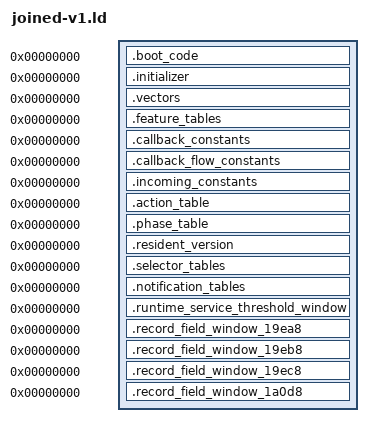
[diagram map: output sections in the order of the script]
OUTPUT_ARCH(riscv)
SECTIONS
{
 .boot_code 0 : SUBALIGN(2) { *(.boot_code)
  *(.text.tsl9_record_dispatch_provider_9658)
  *(.text.tsl9_record_field_transitions_block_9660)
  *(.text.tsl9_record_field_transitions_block_966a)
  *(.text.tsl9_record_field_transitions_block_969c)
  *(.text.tsl9_record_dispatch_provider_973c)
  *(.text.tsl9_record_field_transitions_block_9744)
  *(.text.tsl9_record_field_transitions_block_974e)
  *(.text.tsl9_record_field_transitions_block_978c)
  *(.text.tsl9_record_field_transitions_entry_a4cc)
  *(.text.tsl9_record_field_transitions_entry_a4d8)
  *(.text.tsl9_feature_external_a6d8)
  *(.text.tsl9_record_field_transitions_block_a710)
  *(.text.tsl9_record_field_transitions_block_a71c)
  *(.text.tsl9_record_field_transitions_block_a728)
  *(.text.tsl9_record_field_transitions_block_a734)
  *(.text.tsl9_record_field_transitions_block_a740)
  *(.text.tsl9_record_field_transitions_block_a76c)
  *(.text.tsl9_record_field_transitions_block_a780)
  *(.text.tsl9_record_field_transitions_block_a78c)
  *(.text.tsl9_record_field_transitions_block_a78e)
  *(.text.tsl9_record_field_transitions_block_a7a2)
  *(.text.tsl9_record_field_transitions_block_a7a6)
  *(.text.tsl9_record_field_transitions_block_a7b8)
  *(.text.tsl9_record_field_transitions_block_a7c0)
  *(.text.tsl9_record_field_transitions_block_a7ca)
  *(.text.tsl9_record_field_transitions_block_a7cc)
  *(.text.tsl9_record_field_transitions_block_a7d2)
  *(.text.tsl9_record_field_transitions_block_a7f0)
  *(.text.tsl9_record_field_transitions_block_a7f2)
  *(.text.tsl9_record_field_transitions_block_a7f8)
  *(.text.tsl9_record_field_transitions_block_a80a)
  *(.text.tsl9_record_field_transitions_block_a80e)
  *(.text.tsl9_record_field_transitions_block_a812)
  *(.text.tsl9_record_field_transitions_block_a81c)
  *(.text.tsl9_record_field_transitions_block_a81e)
  *(.text.tsl9_record_field_transitions_block_a824)
  *(.text.tsl9_record_field_transitions_block_a82e)
  *(.text.tsl9_record_field_transitions_block_a836)
  *(.text.tsl9_record_field_transitions_block_a840)
  *(.text.tsl9_record_field_transitions_block_a84a)
  *(.text.tsl9_record_field_transitions_block_a84c)
  *(.text.tsl9_record_field_transitions_block_a850)
  *(.text.tsl9_record_field_transitions_block_a85c)
  *(.text.tsl9_record_field_transitions_block_a85e)
  *(.text.tsl9_record_field_transitions_block_a860)
  *(.text.tsl9_record_field_transitions_block_a866)
  *(.text.tsl9_record_field_transitions_block_a870)
  *(.text.tsl9_record_field_transitions_block_a882)
  *(.text.tsl9_record_field_transitions_block_a888)
  *(.text.tsl9_record_field_transitions_block_a88c)
  *(.text.tsl9_record_field_transitions_block_a890)
  *(.text.tsl9_record_field_transitions_block_a89c)
  *(.text.tsl9_record_field_transitions_block_a8a0)
  *(.text.tsl9_record_field_transitions_block_a8a4)
  *(.text.tsl9_record_field_transitions_block_a8a6)
  *(.text.tsl9_record_field_transitions_block_a8aa)
  *(.text.tsl9_record_field_transitions_block_a8b6)
  *(.text.tsl9_record_field_transitions_block_a8c2)
  *(.text.tsl9_record_field_transitions_block_a8c6)
  *(.text.tsl9_record_field_transitions_block_a8ca)
  *(.text.tsl9_record_field_transitions_block_a8ce)
  *(.text.tsl9_record_field_transitions_block_a8d2)
  *(.text.tsl9_record_field_transitions_block_a8d4)
  *(.text.tsl9_record_field_transitions_block_a8da)
  *(.text.tsl9_record_field_transitions_block_a8e6)
  *(.text.tsl9_record_field_transitions_block_a8ec)
  *(.text.tsl9_record_field_transitions_block_a8f8)
  *(.text.tsl9_record_field_transitions_block_a8fe)
  *(.text.tsl9_record_field_transitions_block_a90c)
  *(.text.tsl9_record_field_transitions_block_a91a)
  *(.text.tsl9_record_field_transitions_block_a91e)
  *(.text.tsl9_record_field_transitions_block_a922)
  *(.text.tsl9_record_field_transitions_block_a93a)
  *(.text.tsl9_record_field_transitions_block_a940)
  *(.text.tsl9_record_field_transitions_block_a944)
  *(.text.tsl9_record_field_transitions_block_a954)
  *(.text.tsl9_record_field_transitions_block_a956)
  *(.text.tsl9_record_field_transitions_block_a95a)
  *(.text.tsl9_record_field_transitions_block_a95e)
  *(.text.tsl9_feature_external_b390)
  *(.text.tsl9_record_field_transitions_block_b3b8)
  *(.text.tsl9_record_field_transitions_block_b3c4)
  *(.text.tsl9_record_field_transitions_block_b3d8)
  *(.text.tsl9_feature_external_b402)
  *(.text.tsl9_record_field_transitions_block_b40c)
  *(.text.tsl9_record_field_transitions_block_b432)
  *(.text.tsl9_record_field_transitions_block_b448)
  *(.text.tsl9_record_field_transitions_block_b45e)
  *(.text.tsl9_record_field_transitions_block_b470)
  *(.text.tsl9_record_field_transitions_block_b484)
  *(.text.tsl9_record_field_transitions_block_b494)
  *(.text.tsl9_record_field_transitions_block_b4a8)
  *(.text.tsl9_record_field_transitions_block_b4bc)
  *(.text.tsl9_record_field_transitions_block_b4c2)
  *(.text.tsl9_record_field_transitions_block_b4c6)
  *(.text.tsl9_record_field_transitions_block_b4ce)
  *(.text.tsl9_record_field_transitions_block_b4d2)
  *(.text.tsl9_record_field_transitions_block_b4d4)
  *(.text.tsl9_record_field_transitions_block_b4e0)
  *(.text.tsl9_record_field_transitions_block_b4e4)
  *(.text.tsl9_record_field_transitions_block_b4e6)
  *(.text.tsl9_record_field_transitions_block_b4ea)
  *(.text.tsl9_record_field_transitions_block_b4ec)
  *(.text.tsl9_record_field_transitions_block_b4fc)
  *(.text.tsl9_record_field_transitions_block_b50e)
  *(.text.tsl9_record_field_transitions_block_b51e)
  *(.text.tsl9_feature_external_c8a2)
  *(.text.tsl9_record_field_transitions_block_c8b4)
  *(.text.tsl9_record_field_transitions_block_c8ba)
  *(.text.tsl9_record_field_transitions_block_c8c6)
  *(.text.tsl9_record_field_transitions_block_c8ce)
  *(.text.tsl9_record_field_transitions_block_c8d8)
  *(.text.tsl9_record_field_transitions_block_c8e4)
  *(.text.tsl9_record_field_transitions_block_c8f6)
  *(.text.tsl9_record_field_transitions_block_c8fa)
  *(.text.tsl9_record_field_transitions_block_c906)
  *(.text.tsl9_record_field_transitions_block_c922)
  *(.text.tsl9_record_field_transitions_block_c92a)
  *(.text.tsl9_record_field_transitions_block_c92e)
  *(.text.tsl9_record_field_transitions_block_c934)
  *(.text.tsl9_record_field_transitions_block_c946)
  *(.text.tsl9_feature_external_c94e)
  *(.text.tsl9_record_field_transitions_block_c960)
  *(.text.tsl9_record_field_transitions_block_c96c)
  *(.text.tsl9_record_field_transitions_block_c976)
  *(.text.tsl9_record_field_transitions_block_c990)
  *(.text.tsl9_record_field_transitions_block_c994)
  *(.text.tsl9_record_field_transitions_block_c99a)
  *(.text.tsl9_record_field_transitions_block_c9a4)
  *(.text.tsl9_record_field_transitions_block_c9aa)
  *(.text.tsl9_record_field_transitions_block_c9b2)
  *(.text.tsl9_record_field_transitions_block_c9b8)
  *(.text.tsl9_record_field_transitions_block_c9be)
  *(.text.tsl9_record_field_transitions_block_c9dc)
  *(.text.tsl9_record_field_transitions_block_c9e2)
  *(.text.tsl9_record_field_transitions_block_ca00)
  *(.text.tsl9_record_field_transitions_block_ca0e)
  *(.text.tsl9_record_field_transitions_block_ca12)
  *(.text.tsl9_record_field_transitions_block_ca1c)
  *(.text.tsl9_record_field_transitions_block_ca3c)
  *(.text.tsl9_record_field_transitions_block_ca46)
  *(.text.tsl9_record_field_transitions_block_ca72)
  *(.text.tsl9_record_field_transitions_block_ca7a)
  *(.text.tsl9_record_field_transitions_block_ca7c)
  *(.text.tsl9_record_field_transitions_block_ca92)
  *(.text.tsl9_record_field_transitions_block_caa2)
  *(.text.tsl9_record_field_transitions_block_cab2)
  *(.text.tsl9_record_field_transitions_block_cac2)
  *(.text.tsl9_record_field_transitions_block_cac4)
  *(.text.tsl9_record_field_transitions_block_cac8)
  *(.text.tsl9_record_field_transitions_block_cacc)
  *(.text.tsl9_record_field_transitions_block_cae2)
  *(.text.tsl9_record_field_transitions_block_cae4)
  *(.text.tsl9_record_field_transitions_block_caee)
  *(.text.tsl9_record_field_transitions_block_caf2)
  *(.text.tsl9_record_field_transitions_block_cafa)
  *(.text.tsl9_record_field_transitions_block_cb18)
  *(.text.tsl9_record_field_transitions_block_cb1a)
  *(.text.tsl9_record_field_transitions_block_cb1c)
  *(.text.tsl9_record_field_transitions_block_cb2e)
  *(.text.tsl9_record_field_transitions_block_cb38)
  *(.text.tsl9_record_field_transitions_block_cb4a)
  *(.text.tsl9_record_field_transitions_block_cb50)
  *(.text.tsl9_record_field_transitions_block_cb66)
  *(.text.tsl9_record_field_transitions_block_cb76)
  *(.text.tsl9_record_field_transitions_block_cb86)
  *(.text.tsl9_record_field_transitions_block_cb96)
  *(.text.tsl9_record_field_transitions_block_cb9a)
  *(.text.tsl9_record_field_transitions_block_cba0)
  *(.text.tsl9_record_field_transitions_block_cba6)
  *(.text.tsl9_record_field_transitions_block_cba8)
  *(.text.tsl9_record_field_transitions_block_cbb4)
  *(.text.tsl9_record_field_transitions_block_cbba)
  *(.text.tsl9_record_field_transitions_block_cbc0)
  *(.text.tsl9_record_field_transitions_block_cbde)
  *(.text.tsl9_record_field_transitions_block_cbee)
  *(.text.tsl9_record_field_transitions_block_cc00)
  *(.text.tsl9_record_field_transitions_block_cc10)
  *(.text.tsl9_record_field_transitions_block_cc38)
  *(.text.tsl9_record_field_transitions_block_cc3e)
  *(.text.tsl9_record_field_transitions_block_cc42)
  *(.text.tsl9_record_field_transitions_block_cc44)
  *(.text.tsl9_feature_external_cec0)
  *(.text.tsl9_feature_external_cedc)
  *(.text.tsl9_record_field_transitions_block_cee6)
  *(.text.tsl9_record_field_transitions_block_cefa)
  *(.text.tsl9_record_field_transitions_block_cf1e)
  *(.text.tsl9_record_field_transitions_block_cf24)
  *(.text.tsl9_record_field_transitions_block_cf36)
  *(.text.tsl9_record_field_transitions_block_cf66)
  *(.text.tsl9_record_field_transitions_block_cf7a)
  *(.text.tsl9_record_field_transitions_block_cf7c)
  *(.text.tsl9_record_field_transitions_block_cf8a)
  *(.text.tsl9_record_field_transitions_block_cf94)
  *(.text.tsl9_feature_external_d14a)
  *(.text.tsl9_record_field_transitions_block_d162)
  *(.text.tsl9_record_field_transitions_block_d16a)
  *(.text.tsl9_record_field_transitions_block_d172)
  *(.text.tsl9_record_field_transitions_block_d17a)
  *(.text.tsl9_record_field_transitions_block_d18e)
  *(.text.tsl9_feature_external_d1b2)
  *(.text.tsl9_record_field_transitions_block_d1bc)
  *(.text.tsl9_record_field_transitions_block_d1c2)
  *(.text.tsl9_record_field_transitions_block_d1cc)
  *(.text.tsl9_record_field_transitions_block_d1e8)
  *(.text.tsl9_record_field_transitions_block_d1ea)
  *(.text.tsl9_record_field_transitions_block_d1f6)
  *(.text.tsl9_record_field_transitions_block_d200)
  *(.text.tsl9_record_field_transitions_block_d224)
  *(.text.tsl9_record_field_transitions_block_d22a)
  *(.text.tsl9_record_field_transitions_block_d234)
  *(.text.tsl9_record_field_transitions_block_d250)
  *(.text.tsl9_record_field_transitions_block_d258)
  *(.text.tsl9_record_field_transitions_block_d260)
  *(.text.tsl9_record_field_transitions_block_d266)
  *(.text.tsl9_record_field_transitions_block_d26c)
  *(.text.tsl9_feature_external_d288)
  *(.text.tsl9_record_field_transitions_block_d2a6)
  *(.text.tsl9_record_field_transitions_block_d2b4)
  *(.text.tsl9_record_field_transitions_block_d2be)
  *(.text.tsl9_record_field_transitions_block_d2c0)
  *(.text.tsl9_record_field_transitions_block_d2d6)
  *(.text.tsl9_record_field_transitions_block_d2e4)
  *(.text.tsl9_feature_external_d378)
  *(.text.tsl9_record_field_transitions_block_d382)
  *(.text.tsl9_record_field_transitions_block_d39e)
  *(.text.tsl9_record_field_transitions_block_d3aa)
  *(.text.tsl9_record_field_transitions_block_d3b8)
  *(.text.tsl9_record_field_transitions_block_d3c4)
  *(.text.tsl9_feature_external_d3f6)
  *(.text.tsl9_record_field_transitions_block_d3fe)
  *(.text.tsl9_record_field_transitions_block_d404)
  *(.text.tsl9_record_field_transitions_block_d406)
  *(.text.tsl9_record_field_transitions_block_d41e)
  *(.text.tsl9_record_field_transitions_block_d426)
  *(.text.tsl9_record_field_transitions_block_d42a)
  *(.text.tsl9_record_field_transitions_block_d45c)
  *(.text.tsl9_record_field_transitions_block_d466)
  *(.text.tsl9_feature_external_d47c)
  *(.text.tsl9_record_field_transitions_block_d488)
  *(.text.tsl9_record_field_transitions_block_d49a)
  *(.text.tsl9_record_field_transitions_block_d4b4)
  *(.text.tsl9_record_field_transitions_block_d4c0)
  *(.text.tsl9_record_field_transitions_block_d4d4)
  *(.text.tsl9_record_field_transitions_block_d4de)
  *(.text.tsl9_feature_external_10288)
  *(.text.tsl9_record_field_transitions_block_102a8)
  *(.text.tsl9_record_field_transitions_block_102aa)
  *(.text.tsl9_record_field_transitions_block_102b2)
  *(.text.tsl9_record_field_transitions_block_102c4)
  *(.text.tsl9_record_field_transitions_block_102cc)
  *(.text.tsl9_record_field_transitions_block_102d2)
  *(.text.tsl9_record_field_transitions_block_102dc)
  *(.text.tsl9_record_field_transitions_block_102de)
  *(.text.tsl9_record_field_transitions_block_102e4)
  *(.text.tsl9_record_field_transitions_block_102ea)
  *(.text.tsl9_record_field_transitions_block_102f0)
  *(.text.tsl9_record_field_transitions_block_102fa)
  *(.text.tsl9_record_field_transitions_block_10300)
  *(.text.tsl9_record_field_transitions_block_10306)
  *(.text.tsl9_record_field_transitions_block_1030a)
  *(.text.tsl9_record_field_transitions_block_1030c)
  *(.text.tsl9_record_field_transitions_block_10314)
  *(.text.tsl9_record_field_transitions_block_10318)
  *(.text.tsl9_record_field_transitions_block_1032a)
  *(.text.tsl9_record_field_transitions_block_1033c)
  *(.text.tsl9_record_field_transitions_block_1034e)
  *(.text.tsl9_record_field_transitions_block_10364)
  *(.text.tsl9_record_field_transitions_block_1037a)
  *(.text.tsl9_record_field_transitions_block_10390)
  *(.text.tsl9_record_field_transitions_block_10394)
  *(.text.tsl9_record_field_transitions_block_10398)
  *(.text.tsl9_record_field_transitions_block_103b0)
  *(.text.tsl9_record_field_transitions_block_103b4)
  *(.text.tsl9_record_field_transitions_block_103bc)
  *(.text.tsl9_record_field_transitions_block_103c6)
  *(.text.tsl9_record_field_transitions_block_103ca)
  *(.text.tsl9_record_field_transitions_block_103da)
  *(.text.tsl9_record_field_transitions_block_103ea)
  *(.text.tsl9_record_field_transitions_block_103ee)
  *(.text.tsl9_record_field_transitions_block_103f8)
  *(.text.tsl9_feature_external_10440)
  *(.text.tsl9_record_field_transitions_block_10470)
  *(.text.tsl9_record_field_transitions_block_10474)
  *(.text.tsl9_record_field_transitions_block_1047a)
  *(.text.tsl9_record_field_transitions_block_1048e)
  *(.text.tsl9_record_field_transitions_block_10492)
  *(.text.tsl9_record_field_transitions_block_104aa)
  *(.text.tsl9_record_field_transitions_block_104ac)
  *(.text.tsl9_record_field_transitions_block_104b4)
  *(.text.tsl9_record_field_transitions_block_104b8)
  *(.text.tsl9_record_field_transitions_block_104c2)
  *(.text.tsl9_record_field_transitions_block_104ce)
  *(.text.tsl9_record_field_transitions_block_104d8)
  *(.text.tsl9_record_field_transitions_block_104e2)
  *(.text.tsl9_record_field_transitions_block_104e4)
  *(.text.tsl9_record_field_transitions_block_104ec)
  *(.text.tsl9_record_field_transitions_block_104f8)
  *(.text.tsl9_record_field_transitions_block_10500)
  *(.text.tsl9_record_field_transitions_block_1050c)
  *(.text.tsl9_record_field_transitions_block_10512)
  *(.text.tsl9_record_field_transitions_block_1051a)
  *(.text.tsl9_record_field_transitions_block_10526)
  *(.text.tsl9_record_field_transitions_block_1052e)
  *(.text.tsl9_record_field_transitions_block_1053a)
  *(.text.tsl9_record_field_transitions_block_10542)
  *(.text.tsl9_record_field_transitions_block_1054e)
 }
 .initializer 0 : SUBALIGN(4) { *(.initializer) }
 .vectors 0 : SUBALIGN(4) { *(.vectors) }
 .feature_tables 0 : SUBALIGN(4) { *(.feature_tables) }
 .callback_constants 0 : SUBALIGN(4) { *(.callback_constants) }
 .callback_flow_constants 0 : SUBALIGN(4) { *(.callback_flow_constants) }
 .incoming_constants 0 : SUBALIGN(4) { *(.incoming_constants) }
 .action_table 0 : SUBALIGN(4) { *(.action_table) }
 .phase_table 0 : SUBALIGN(4) { *(.phase_table) }
 .resident_version 0 : SUBALIGN(4) { *(.resident_version) }
 .selector_tables 0 : SUBALIGN(1) {
  *(.rodata.tsl9_feature_state_records_static_data_1a4e4)
  *(.rodata.tsl9_feature_state_records_static_data_1a518)
  *(.rodata.tsl9_feature_state_records_static_data_1a528)
  *(.rodata.tsl9_feature_state_records_static_data_1a538)
 }
 .notification_tables 0 : SUBALIGN(4) {
  *(.rodata.tsl9_selector_notifications_table_1a13c)
  *(.rodata.tsl9_selector_notifications_table_1a150)
  *(.rodata.tsl9_selector_notifications_table_1a1c8)
  *(.rodata.tsl9_selector_notifications_table_1a314)
  *(.rodata.tsl9_selector_notifications_table_1a33c)
 }
 .runtime_service_threshold_window 0 : SUBALIGN(1) { *(.runtime_service_threshold_window) }
 .record_field_window_19ea8 0 : SUBALIGN(1) { *(.rodata.tsl9_record_field_transitions_data_19ea8) }
 .record_field_window_19eb8 0 : SUBALIGN(1) { *(.rodata.tsl9_record_field_transitions_data_19eb8) }
 .record_field_window_19ec8 0 : SUBALIGN(1) { *(.rodata.tsl9_record_field_transitions_data_19ec8) }
 .record_field_window_1a0d8 0 : SUBALIGN(1) { *(.rodata.tsl9_record_field_transitions_data_1a0d8) }
 /DISCARD/ : { *(.comment) *(.riscv.attributes) *(.llvm_addrsig) }
}
